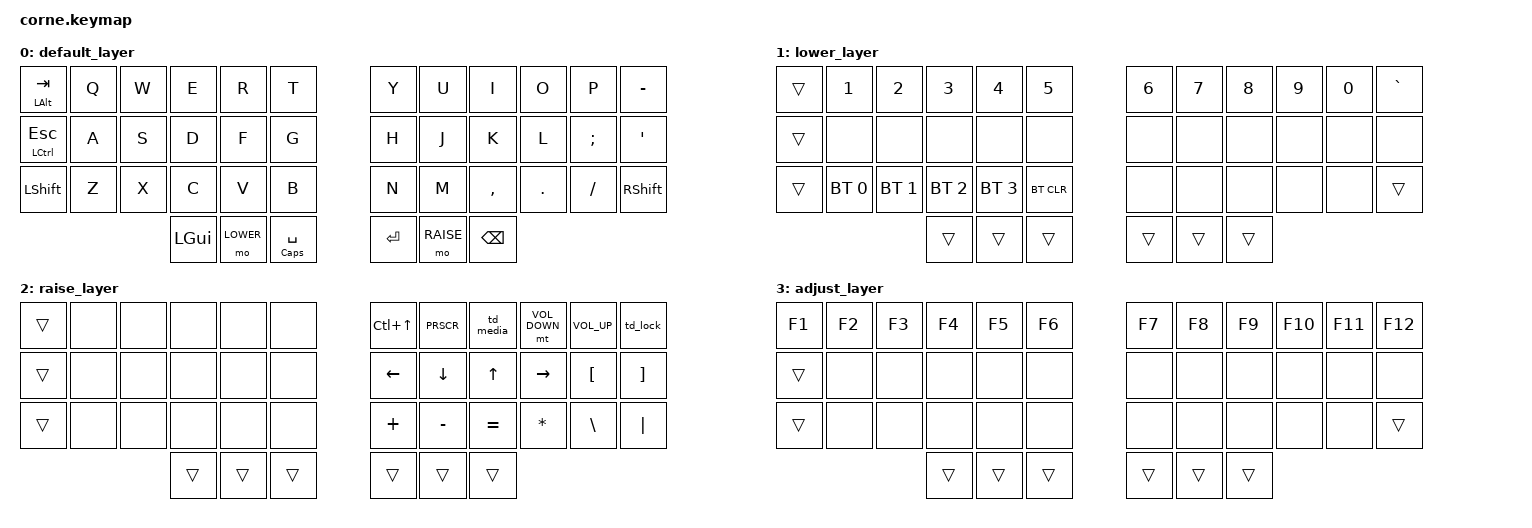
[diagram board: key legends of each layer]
/*
 * Copyright (c) 2022 Aleksandar Diklic
 *
  * SPDX-License-Identifier: MIT
 */

#include <behaviors.dtsi>
#include <dt-bindings/zmk/keys.h>
#include <dt-bindings/zmk/bt.h>

#define TAPPING_TERM 200
#define COMBO_TIMEOUT 40

#define DEFAULT 0
#define LOWER 1
#define RAISE 2
#define ADJUST 3

#define PRSCR LS(LC(LG(N4)))

// Friendlier volume definitions, tap volume down, hold mute
#define VOLUME_DOWN K_MUTE C_VOLUME_DOWN
#define VOLUME_UP C_VOLUME_UP

&kscan0 {
    debounce-press-ms = <10>;
    debounce-release-ms = <10>;
};

&mt {
    tapping-term-ms = <TAPPING_TERM>;
    flavor = "tap-preferred";
};

/ {
  behaviors {
    /*
    * td_media mimics the behavior of AirPods controls:
    *  - tap once for play / pause
    *  - tap twice for next track
    *  - tap three times for previous track
    */
    td_media: tap_dance_media {
      compatible = "zmk,behavior-tap-dance";
      label = "TAP_DANCE_MEDIA";
      #binding-cells = <0>;
      tapping-term-ms = <TAPPING_TERM>;
      bindings = <&kp C_PLAY_PAUSE>, <&kp C_NEXT>, <&kp C_PREVIOUS>;
    };

    /*
    * td_lock groups locking functions into one key:
    *  - tap once to lock the host
    *  - tap twice to put the host to sleep
    */
    td_lock: tap_dance_lock {
      compatible = "zmk,behavior-tap-dance";
      label = "TAP_DANCE_LOCK";
      #binding-cells = <0>;
      tapping-term-ms = <TAPPING_TERM>;
      bindings = <&kp LG(LC(Q))>, <&kp LG(LA(C_EJECT))>;
    };
  };

  conditional_layers {
    compatible = "zmk,conditional-layers";
    tri_layer {
      if-layers = <LOWER RAISE>;
      then-layer = <ADJUST>;
    };
  };

  combos {
    compatible = "zmk,combos";

    combo_cmd_space {
      timeout-ms = <50>;
      key-positions = <38 39>;
      bindings = <&kp LG(SPACE)>;
    };
  };

  keymap {
    compatible = "zmk,keymap";

    // key positions
    /* --------------------------------------------------------------------------------
    *  |  0  |  1  |  2  |  3  |  4  |  5  |     |  6  |  7  |  8  |  9  |  10 |  11 |
    *  |  12 |  13 |  14 |  15 |  16 |  17 |     |  18 |  19 |  20 |  21 |  22 |  23 |
    *  |  24 |  25 |  26 |  27 |  28 |  29 |     |  30 |  31 |  32 |  33 |  34 |  35 |
    *                    |  36 |  37 |  38 |     |  39 |  40 |  41 |
    */

    default_layer {
     bindings = <
        &mt LALT TAB &kp Q &kp W &kp E    &kp R     &kp T             &kp Y   &kp U     &kp I     &kp O   &kp P    &kp MINUS
        &mt LCTL ESC &kp A &kp S &kp D    &kp F     &kp G             &kp H   &kp J     &kp K     &kp L   &kp SEMI &kp SQT
        &kp LSHFT    &kp Z &kp X &kp C    &kp V     &kp B             &kp N   &kp M     &kp COMMA &kp DOT &kp FSLH &kp RSHFT
                                 &kp LGUI &mo LOWER &mt CAPS SPACE    &kp RET &mo RAISE &kp BSPC
      >;
    };

    lower_layer {
     bindings = <
        &trans &kp N1       &kp N2       &kp N3       &kp N4       &kp N5         &kp N6 &kp N7 &kp N8 &kp N9 &kp N0 &kp GRAVE
        &trans &none        &none        &none        &none        &none          &none  &none  &none  &none  &none  &none
        &trans &bt BT_SEL 0 &bt BT_SEL 1 &bt BT_SEL 2 &bt BT_SEL 3 &bt BT_CLR     &none  &none  &none  &none  &none  &trans
                                        &trans       &trans       &trans         &trans &trans &trans
      >;
    };

    raise_layer {
     bindings = <
        &trans &none &none &none  &none  &none      &kp LC(UP) &kp PRSCR &td_media &mt VOLUME_DOWN &kp VOLUME_UP &td_lock
        &trans &none &none &none  &none  &none      &kp LEFT   &kp DOWN  &kp UP    &kp RIGHT       &kp LBKT      &kp RBKT
        &trans &none &none &none  &none  &none      &kp PLUS   &kp MINUS &kp EQUAL &kp STAR        &kp BSLH      &kp PIPE
                           &trans &trans &trans     &trans     &trans    &trans
      >;
    };

    adjust_layer {
     bindings = <
        &kp F1 &kp F2 &kp F3 &kp F4 &kp F5 &kp F6     &kp F7 &kp F8 &kp F9 &kp F10 &kp F11 &kp F12
        &trans &none  &none  &none  &none  &none      &none  &none  &none  &none   &none   &none
        &trans &none  &none  &none  &none  &none      &none  &none  &none  &none   &none   &trans
                             &trans &trans &trans     &trans &trans &trans
      >;
    };
  };
};
